# F28x7x_memory_error_regs register map
Vendor: Texas Instruments
Peripheral module from a debugger description file (folder C2000).
Address unit: 16 bits
Registers are 32-bit, read-only, no defined reset value unless marked. A register's access mark holds for its fields unless they carry their own. Offsets are as the file gives them; lines under a group give offsets from that group; [hi:lo] are bit positions; {n}, {i} and the like mark numbered series; 'fields as' and 'values as' point back to an identical list; <NAME> marks a mode.

## MEMORY_ERROR_REGS — MEMORY ERROR Registers
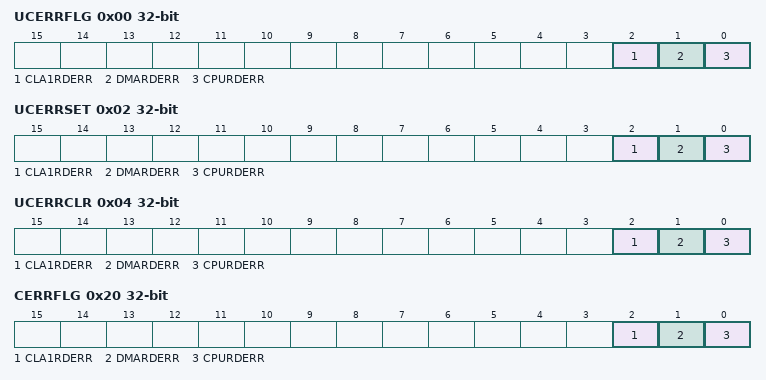
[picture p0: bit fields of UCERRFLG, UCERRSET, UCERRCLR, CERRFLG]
0x00 UCERRFLG — Uncorrectable Error Flag Register
  [2] CLA1RDERR — CLA1 Uncorrectable Read Error Flag
  [1] DMARDERR — DMA Uncorrectable Read Error Flag
  [0] CPURDERR — CPU Uncorrectable Read Error Flag
0x02 UCERRSET access not given — Uncorrectable Error Flag Set Register
  [2] CLA1RDERR — CLA1 Uncorrectable Read Error Flag Set (access R=0/W=1)
  [1] DMARDERR — DMA Uncorrectable Read Error Flag Set (access R=0/W=1)
  [0] CPURDERR — CPU Uncorrectable Read Error Flag Set (access R=0/W=1)
0x04 UCERRCLR access not given — Uncorrectable Error Flag Clear Register
  [2] CLA1RDERR — CLA1 Uncorrectable Read Error Flag Clear (access R=0/W=1)
  [1] DMARDERR — DMA Uncorrectable Read Error Flag Clear (access R=0/W=1)
  [0] CPURDERR — CPU Uncorrectable Read Error Flag Clear (access R=0/W=1)
0x06 UCCPUREADDR — Uncorrectable CPU Read Error Address
  [31:0] UCCPUREADDR — Uncorrectable CPU read/fetch access address register.
0x08 UCDMAREADDR — Uncorrectable DMA Read Error Address
  [31:0] UCDMAREADDR — Uncorrectable DMA read access address register.
0x0A UCCLA1READDR — Uncorrectable CLA1 Read Error Address
  [31:0] UCCLA1READDR — Uncorrectable CLA1 read/fetch access address register.
0x20 CERRFLG — Correctable Error Flag Register
  [2] CLA1RDERR — CLA1 Correctable Read Error Flag
  [1] DMARDERR — DMA Correctable Read Error Flag
  [0] CPURDERR — CPU Correctable Read Error Flag
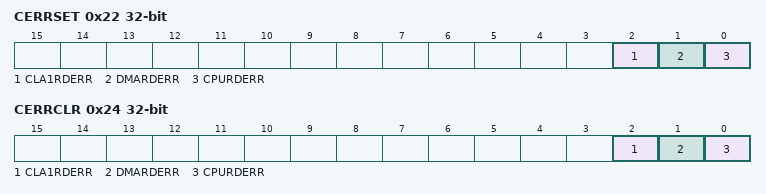
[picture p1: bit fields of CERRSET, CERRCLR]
0x22 CERRSET access not given — Correctable Error Flag Set Register
  [2] CLA1RDERR — CLA1 Correctable Read Error Flag Set (access R=0/W=1)
  [1] DMARDERR — DMA Correctable Read Error Flag Set (access R=0/W=1)
  [0] CPURDERR — CPU Correctable Read Error Flag Set (access R=0/W=1)
0x24 CERRCLR access not given — Correctable Error Flag Clear Register
  [2] CLA1RDERR — CLA1 Correctable Read Error Flag Clear (access R=0/W=1)
  [1] DMARDERR — DMA Correctable Read Error Flag Clear (access R=0/W=1)
  [0] CPURDERR — CPU Correctable Read Error Flag Clear (access R=0/W=1)
0x26 CCPUREADDR — Correctable CPU Read Error Address
  [31:0] CCPUREADDR — Correctable CPU read/fetch access address register.
0x2E CERRCNT — Correctable Error Count Register
  [31:0] CERRCNT — Correctable error count.
0x30 CERRTHRES rw — Correctable Error Threshold Value Register
  [31:0] CERRTHRES — Correctable error threshold.
0x32 CEINTFLG — Correctable Error Interrupt Flag Status Register
  [0] CEINTFLAG — Total corrected error count exceeded threshold flag.
0x34 CEINTCLR access not given — Correctable Error Interrupt Flag Clear Register
  [0] CEINTCLR — CPU Corrected Error Threshold Exceeded Error Clear. (access R=0/W=1)
0x36 CEINTSET access not given — Correctable Error Interrupt Flag Set Register
  [0] CEINTSET — Total corrected error count exceeded flag set. (access R=0/W=1)
0x38 CEINTEN rw — Correctable Error Interrupt Enable Register
  [0] CEINTEN — CPU/DMA Correctable Error Interrupt Enable.
